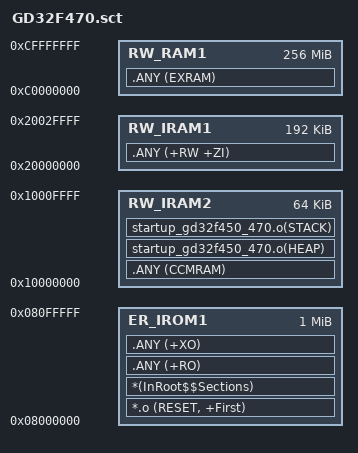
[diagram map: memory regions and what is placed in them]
; ******************************************************************
; *** Scatter-Loading Description File generated by Embedded IDE ***
; ******************************************************************

LR_IROM1 0x08000000 0x00100000 {
	ER_IROM1 0x08000000 0x00100000 {
		*.o (RESET, +First) 
		*(InRoot$$Sections) 
		.ANY (+RO) 
		.ANY (+XO) 
	}


	RW_IRAM1 0x20000000 0x00030000 {
		.ANY (+RW +ZI) 
	}
    RW_IRAM2 0x10000000 0x00010000 {
        .ANY (CCMRAM) 
		startup_gd32f450_470.o(HEAP)
        startup_gd32f450_470.o(STACK)
        ;加载FreeRTOS系统相关文件
        ;croutine.o(+RW +ZI)
        ;event_groups.o (+RW +ZI)
        ;list.o (+RW +ZI)
        ;queue.o (+RW +ZI)
        ;stream_buffer.o
        ;tasks.o (+RW +ZI)
        ;timers.o (+RW +ZI)
        ;heap_4.o (+RW +ZI)
        ;port.o(+RW +ZI)
        
        ;加载用户相关文件 注意F407的第二存储空间只有64K
        ;mid_share_data.o(+RW +ZI)
        ;mid_param.o(+RW +ZI)
	}
	RW_RAM1 0xC0000000 0x10000000 {
		.ANY (EXRAM) 
	}
}

